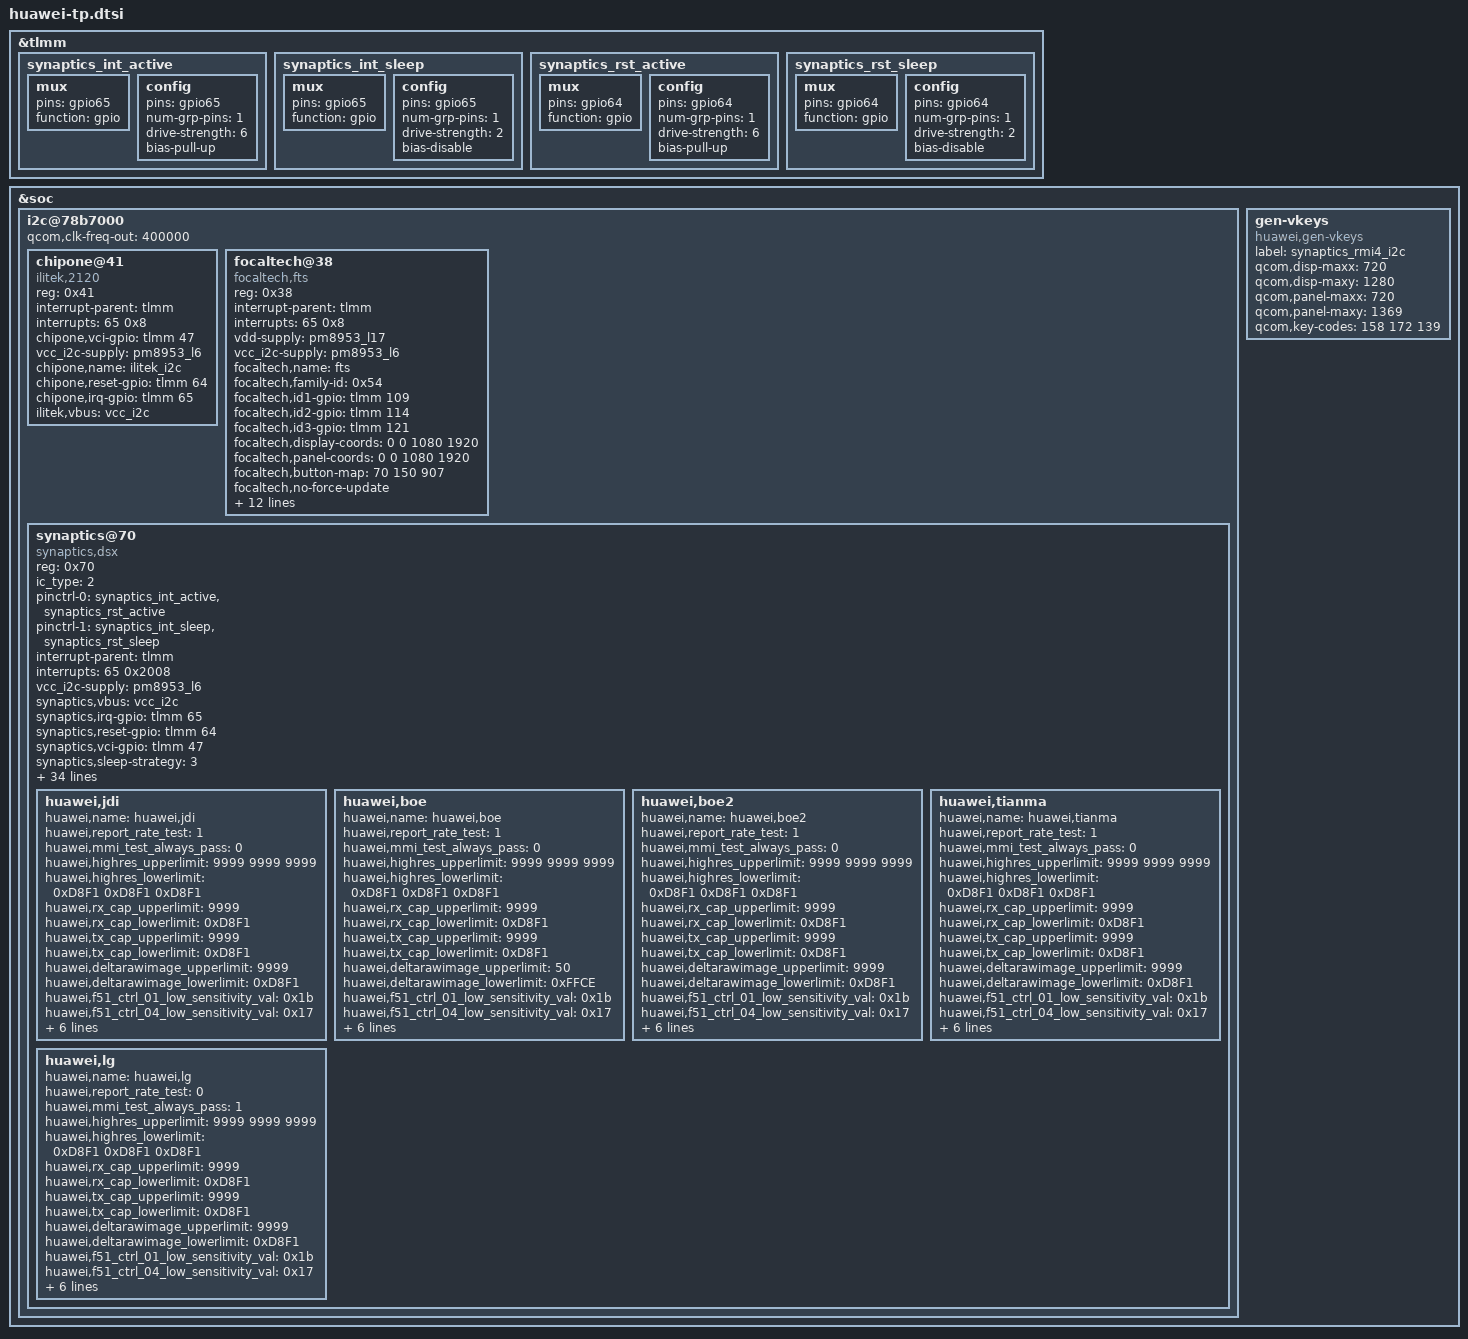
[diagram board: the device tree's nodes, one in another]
/* Modify JDI tp/lcd power on/off to reduce power consumption */
/* Modify JDI tp reset gpio pinctrl for power consumption */
/*Ath TP not working in glove mode*/
/* move l16 control to ATH device config file */
&tlmm {
	synaptics_int_active: synaptics_int_active{
			mux {
				pins = "gpio65";
				function =  "gpio";
			};
			config {
				pins = "gpio65";
				num-grp-pins = <1>;
				drive-strength = <6>;
				bias-pull-up;
		};
	};
	synaptics_int_sleep: synaptics_int_sleep {
			mux {
				pins = "gpio65";
				function =  "gpio";
			};
			config {
				pins = "gpio65";
				num-grp-pins = <1>;
				drive-strength = <2>;
				bias-disable;
		};
	};
	synaptics_rst_active: synaptics_rst_active {
			mux {
				pins = "gpio64";
				function =  "gpio";
			};
			config {
				pins = "gpio64";
				num-grp-pins = <1>;
				drive-strength = <6>;
				bias-pull-up;
			};
		};
	synaptics_rst_sleep: synaptics_rst_sleep {
			mux {
				pins = "gpio64";
				function =  "gpio";
			};
			config {
				pins = "gpio64";
				num-grp-pins = <1>;
				drive-strength = <2>;
				bias-disable;
		};
	};
};

&soc {
	i2c@78b7000 { /* BLSP1 QUP5 */
		status = "ok";
		#address-cells = <1>;
		#size-cells = <0>;
		qcom,clk-freq-out = <400000>;
		chipone@41{
			compatible = "ilitek,2120";
			reg = <0x41>;
			interrupt-parent = <&tlmm>;
			interrupts = <65 0x8>;
			chipone,vci-gpio = <&tlmm 47 0x0>;
			vcc_i2c-supply = <&pm8953_l6>;
			chipone,name = "ilitek_i2c";
			chipone,reset-gpio = <&tlmm 64 0x00>;
			chipone,irq-gpio = <&tlmm 65 0x00>;
			ilitek,vbus = "vcc_i2c";
		};
		focaltech@38 {
		compatible = "focaltech,fts"; 
		reg = <0x38>; 
		interrupt-parent = <&tlmm>; 
		interrupts = <65 0x8>; 
		vdd-supply = <&pm8953_l17>;
		vcc_i2c-supply = <&pm8953_l6>;
		focaltech,name = "fts"; 
		focaltech,family-id = <0x54>; 
		//focaltech,reset-gpio = <&tlmm 64 0x00>; 
		//focaltech,irq-gpio =<&tlmm 65 0x00>; 
		focaltech,id1-gpio = <&tlmm 109 0x00>; 
		focaltech,id2-gpio = <&tlmm 114 0x00>; 
		focaltech,id3-gpio = <&tlmm 121 0x00>; 
		focaltech,display-coords = <0 0 1080 1920>; 
		focaltech,panel-coords = <0 0 1080 1920>; 
		focaltech,button-map= <70 150 907>; 
		focaltech,no-force-update; 
		focaltech,i2c-pull-up; 
		focaltech,group-id = <1>; 
		focaltech,hard-reset-delay-ms = <20>; 
		focaltech,soft-reset-delay-ms = <150>; 
		focaltech,num-max-touches = <10>; 
		focaltech,fw-name = "FT_Upgrade_App.i"; 
		focaltech,fw-delay-aa-ms = <50>; 
		focaltech,fw-delay-55-ms = <30>; 
		focaltech,fw-upgrade-id1 = <0x79>; 
		focaltech,fw-upgrade-id2 = <0x03>; 
		focaltech,fw-delay-readid-ms = <10>; 
		focaltech,fw-delay-era-flsh-ms = <2000>;		
		};
		synaptics@70 {
			compatible = "synaptics,dsx";
			reg = <0x70>;

			/* SYNAPTICS_S3207 = 0 */
			/* SYNAPTICS_S3350 = 1 */
			/* SYNAPTICS_S3320 = 2 */
			/* SYNAPTICS_S3718 = 3 */
			ic_type = <2>;

			pinctrl-names = "active","sleep";
			pinctrl-0 = <&synaptics_int_active &synaptics_rst_active>;
			pinctrl-1 = <&synaptics_int_sleep &synaptics_rst_sleep>;

			interrupt-parent = <&tlmm>;
			interrupts = <65 0x2008>;
			//vdd-supply = <&pm8953_l17>;
			vcc_i2c-supply = <&pm8953_l6>;
			/* Some of qcom's param will not be replaced by huawei in dtb, */
			/* just ignore them:such as "pinctrl-names","pinctrl-0","pinctrl-1", */
			/* "synaptics,display-coords","synaptics,panel-coords","synaptics,i2c-pull-up", */
			/* "synaptics,power-down","synaptics,disable-gpios"*/
			//synaptics,vdd = "vdd";
			synaptics,vbus = "vcc_i2c";
			synaptics,irq-gpio = <&tlmm 65 0x2008>;
			synaptics,reset-gpio = <&tlmm 64 0x0>;
			synaptics,vci-gpio = <&tlmm 47 0x0>;

			/* synaptics,sleep/wake strategy */

			/* SLEEP_STRATEGY_DEEP_SLEEP    : 0*/
			/* SLEEP_STRATEGY_POWER_DOWN    : 1*/
			/* SLEEP_STRATEGY_KEEP_WAKE     : 2*/
			/* SLEEP_STRATEGY_ALWAYS_RESET  : 3*/
			synaptics,sleep-strategy = <3>;

			synaptics,lcd-x = <1080>;
			synaptics,lcd-y = <1920>;
			synaptics,lcd-all = <1920>;
			synaptics,virtual_keys = /* KeyCode CenterX CenterY Width Height */
				/* KEY_BACK */
				<158 142 1342 150 100
				/* KEY_HOME(172) */
				172 360 1342 150 100
				/* KEY_MENU */
				139 578 1342 150 100>;
			synaptics,shutdown_flag = <1>;
			synaptics,appinfo_display_flag = <1>;
			/* SYNAPTICS_WAKE_UP_GESTURE_FLAG:'1'->enabled,'0'->disabled */
			/*IC flash is not enough for holster,so fw del one gesture*/
			synaptics,gesture_enabled = <0>;
			/* Gestures that supported:                           */
			/* bit0  Double tap                                        */
			/* bit1  Single finger slide from left to right     */
			/* bit2  Single finger slide from right to left     */
			/* bit3  Single finger slide from top to bottom  */
			/* bit4  Single finger slide from bottom to top  */
			/* bit5  Double finger slide from top to bottom--disable for holster*/
			/* bit6  Single finger slide circle                     */
			/* bit7  Single finger write letter c                  */
			/* bit8  Single finger write letter e                  */
			/* bit9  Single finger write letter m                 */
			/* bit10 Single finger write letter w                 */
			/* bit11 Palm off screen                                */
			synaptics,easy_wakeup_supported_gestures = <0xF81>;

			/*Defination of report key value  for different gestures*/
			synaptics,easy_wakeup_gesture_keys =
			<	59 /*0.Double tap:                                  KEY_F1*/
				60 /*1.Single finger slide from left to right:      KEY_F2*/
				61 /*2.Single finger slide from right to left:      KEY_F3*/
				62 /*3.Single finger slide from top to bottom:      KEY_F4*/
				63 /*4.Single finger slide from bottom to top:      KEY_F5*/
				64 /*5.Single finger slide circle clockwise:        KEY_F6*/
				65 /*6.Single finger slide circle counter-clockwise:KEY_F7*/
				66 /*7.Single finger write letter c:                KEY_F8*/
				67 /*8.Single finger write letter e:                KEY_F9*/
				68 /*9.Single finger write letter m:                KEY_F10*/
				87 /*10.Single finger write letter w:               KEY_F11*/
				88 /*11.Palm off screen:                            KEY_F12*/
			>;

			/* Double-tap-zone defined by huawei */
			/* Shielded area is:1cm left,1cm right,3cm up,2cm down */
			huawei,dtz_x0 = <1>;
			huawei,dtz_y0 = <1>;
			huawei,dtz_x1 = <1080>;
			huawei,dtz_y1 = <1920>;

			/* GLOVE FLAG default state:'1'->enabled,'0'->disabled*/
			synaptics,glove_enabled = <0>;
			/*After reduce power-consumption by exit reduce mode,*/
			/*we have to reduce f-r rate to make sure gesture work fine*/
			synaptics,fast_relax_gesture = <0>;
			/*Holster support flag*/
			synaptics,holster_supported = <1>;
			synaptics,glove_edge_switch_supported = <0>;
			synaptics,grip_algorithm_supported = <0>;
			synaptics,grip_algorithm_enabled = <0>;
			huawei,grip_left_lsb = <0x32>;
			huawei,grip_left_msb = <0x0>;
			huawei,grip_right_lsb = <0x1A>;
			huawei,grip_right_msb = <0x04>;

			/*dwt represent doze wakeup threshold in gesture mode*/
			synaptics,ofilm_dwt = <30>;
			synaptics,truly_dwt = <30>;
			synaptics,junda_dwt = <30>;

			synaptics,reset-on-status = <0>;
			synaptics,power-delay-ms = <160>;
			synaptics,reset-delay-ms = <200>;
			synaptics,reset-active-ms = <10>;
			synaptics,product_name = "cannes";

			/*capacitance self-adapt*/
			huawei,jdi {
				huawei,name = "huawei,jdi";
				huawei,report_rate_test = <1>; /* 0:disable test, 1:enable test */
				huawei,mmi_test_always_pass = <0>;

				huawei,highres_upperlimit = <9999 9999 9999>;
				huawei,highres_lowerlimit = <0xD8F1 0xD8F1 0xD8F1>;/* 0xD8F1 == -9999 */

				huawei,rx_cap_upperlimit = <9999>;
				huawei,rx_cap_lowerlimit = <0xD8F1>;

				huawei,tx_cap_upperlimit = <9999>;
				huawei,tx_cap_lowerlimit = <0xD8F1>;

				huawei,deltarawimage_upperlimit = <9999>;
				huawei,deltarawimage_lowerlimit = <0xD8F1>;

				huawei,f51_ctrl_01_low_sensitivity_val = <0x1b>;
				huawei,f51_ctrl_04_low_sensitivity_val = <0x17>;
				huawei,f01_ctrl_05_low_sensitivity_val = <0x05>;
				huawei,f01_ctrl_09_low_sensitivity_val = <0x04>;

				huawei,fullraw_upperlimit =
					<9999 9999 9999 9999 9999 9999 9999 9999 9999 9999 9999 9999 9999 9999 9999 9999 9999 9999 9999 9999 9999 9999 9999 9999 9999 9999 9999 9999
					9999 9999 9999 9999 9999 9999 9999 9999 9999 9999 9999 9999 9999 9999 9999 9999 9999 9999 9999 9999 9999 9999 9999 9999 9999 9999 9999 9999
					9999 9999 9999 9999 9999 9999 9999 9999 9999 9999 9999 9999 9999 9999 9999 9999 9999 9999 9999 9999 9999 9999 9999 9999 9999 9999 9999 9999
					9999 9999 9999 9999 9999 9999 9999 9999 9999 9999 9999 9999 9999 9999 9999 9999 9999 9999 9999 9999 9999 9999 9999 9999 9999 9999 9999 9999
					9999 9999 9999 9999 9999 9999 9999 9999 9999 9999 9999 9999 9999 9999 9999 9999 9999 9999 9999 9999 9999 9999 9999 9999 9999 9999 9999 9999
					9999 9999 9999 9999 9999 9999 9999 9999 9999 9999 9999 9999 9999 9999 9999 9999 9999 9999 9999 9999 9999 9999 9999 9999 9999 9999 9999 9999
					9999 9999 9999 9999 9999 9999 9999 9999 9999 9999 9999 9999 9999 9999 9999 9999 9999 9999 9999 9999 9999 9999 9999 9999 9999 9999 9999 9999
					9999 9999 9999 9999 9999 9999 9999 9999 9999 9999 9999 9999 9999 9999 9999 9999 9999 9999 9999 9999 9999 9999 9999 9999 9999 9999 9999 9999
					9999 9999 9999 9999 9999 9999 9999 9999 9999 9999 9999 9999 9999 9999 9999 9999 9999 9999 9999 9999 9999 9999 9999 9999 9999 9999 9999 9999
					9999 9999 9999 9999 9999 9999 9999 9999 9999 9999 9999 9999 9999 9999 9999 9999 9999 9999 9999 9999 9999 9999 9999 9999 9999 9999 9999 9999
					9999 9999 9999 9999 9999 9999 9999 9999 9999 9999 9999 9999 9999 9999 9999 9999 9999 9999 9999 9999 9999 9999 9999 9999 9999 9999 9999 9999
					9999 9999 9999 9999 9999 9999 9999 9999 9999 9999 9999 9999 9999 9999 9999 9999 9999 9999 9999 9999 9999 9999 9999 9999 9999 9999 9999 9999
					9999 9999 9999 9999 9999 9999 9999 9999 9999 9999 9999 9999 9999 9999 9999 9999 9999 9999 9999 9999 9999 9999 9999 9999 9999 9999 9999 9999
					9999 9999 9999 9999 9999 9999 9999 9999 9999 9999 9999 9999 9999 9999 9999 9999 9999 9999 9999 9999 9999 9999 9999 9999 9999 9999 9999 9999
					9999 9999 9999 9999 9999 9999 9999 9999 9999 9999 9999 9999 9999 9999 9999 9999 9999 9999 9999 9999 9999 9999 9999 9999 9999 9999 9999 9999
					9999 9999 9999 9999 9999 9999 9999 9999 9999 9999 9999 9999 9999 9999 9999 9999 9999 9999 9999 9999 9999 9999 9999 9999 9999 9999 9999 9999>;

				huawei,fullraw_lowerlimit =
					<0 0 0 0 0 0 0 0 0 0 0 0 0 0 0 0 0 0 0 0 0 0 0 0 0 0 0 0
					0 0 0 0 0 0 0 0 0 0 0 0 0 0 0 0 0 0 0 0 0 0 0 0 0 0 0 0
					0 0 0 0 0 0 0 0 0 0 0 0 0 0 0 0 0 0 0 0 0 0 0 0 0 0 0 0
					0 0 0 0 0 0 0 0 0 0 0 0 0 0 0 0 0 0 0 0 0 0 0 0 0 0 0 0
					0 0 0 0 0 0 0 0 0 0 0 0 0 0 0 0 0 0 0 0 0 0 0 0 0 0 0 0
					0 0 0 0 0 0 0 0 0 0 0 0 0 0 0 0 0 0 0 0 0 0 0 0 0 0 0 0
					0 0 0 0 0 0 0 0 0 0 0 0 0 0 0 0 0 0 0 0 0 0 0 0 0 0 0 0
					0 0 0 0 0 0 0 0 0 0 0 0 0 0 0 0 0 0 0 0 0 0 0 0 0 0 0 0
					0 0 0 0 0 0 0 0 0 0 0 0 0 0 0 0 0 0 0 0 0 0 0 0 0 0 0 0
					0 0 0 0 0 0 0 0 0 0 0 0 0 0 0 0 0 0 0 0 0 0 0 0 0 0 0 0
					0 0 0 0 0 0 0 0 0 0 0 0 0 0 0 0 0 0 0 0 0 0 0 0 0 0 0 0
					0 0 0 0 0 0 0 0 0 0 0 0 0 0 0 0 0 0 0 0 0 0 0 0 0 0 0 0
					0 0 0 0 0 0 0 0 0 0 0 0 0 0 0 0 0 0 0 0 0 0 0 0 0 0 0 0
					0 0 0 0 0 0 0 0 0 0 0 0 0 0 0 0 0 0 0 0 0 0 0 0 0 0 0 0
					0 0 0 0 0 0 0 0 0 0 0 0 0 0 0 0 0 0 0 0 0 0 0 0 0 0 0 0
					0 0 0 0 0 0 0 0 0 0 0 0 0 0 0 0 0 0 0 0 0 0 0 0 0 0 0 0>;
			};

			huawei,boe {
				huawei,name = "huawei,boe";
				huawei,report_rate_test = <1>; /* 0:disable test, 1:enable test */
				huawei,mmi_test_always_pass = <0>;

				huawei,highres_upperlimit = <9999 9999 9999>;
				huawei,highres_lowerlimit = <0xD8F1 0xD8F1 0xD8F1>;/* 0xD8F1 == -9999 */

				huawei,rx_cap_upperlimit = <9999>;
				huawei,rx_cap_lowerlimit = <0xD8F1>;

				huawei,tx_cap_upperlimit = <9999>;
				huawei,tx_cap_lowerlimit = <0xD8F1>;

				huawei,deltarawimage_upperlimit = <50>;
				huawei,deltarawimage_lowerlimit = <0xFFCE>;

				huawei,f51_ctrl_01_low_sensitivity_val = <0x1b>;
				huawei,f51_ctrl_04_low_sensitivity_val = <0x17>;
				huawei,f01_ctrl_05_low_sensitivity_val = <0x05>;
				huawei,f01_ctrl_09_low_sensitivity_val = <0x04>;

				huawei,fullraw_upperlimit =
					<3447 3363 3309 3248 3208 3193 3177 3184 3190 3195 3194 3244 3314 3373 3487
					3306 3187 3126 3080 3043 3027 3013 3015 3013 3046 3025 3073 3136 3177 3289
					3314 3181 3111 3072 3032 3022 3016 3016 3007 3042 3025 3076 3111 3169 3298
					3316 3190 3117 3060 3020 3016 3020 3027 3016 3042 3030 3064 3111 3169 3306
					3321 3177 3114 3069 3025 3019 3025 3032 3022 3046 3043 3072 3116 3174 3308
					3328 3187 3117 3067 3030 3022 3027 3033 3027 3054 3046 3079 3117 3174 3312
					3330 3194 3121 3067 3030 3026 3032 3042 3027 3052 3050 3086 3138 3208 3312
					3328 3195 3126 3069 3036 3026 3037 3050 3037 3056 3057 3104 3168 3235 3309
					3314 3188 3120 3060 3033 3016 3037 3046 3033 3045 3052 3090 3168 3231 3292
					3322 3184 3123 3072 3033 3030 3037 3049 3033 3056 3064 3110 3178 3244 3302
					3315 3181 3114 3072 3026 3026 3032 3042 3027 3052 3063 3109 3169 3230 3292
					3312 3181 3114 3062 3027 3026 3032 3037 3027 3052 3050 3094 3153 3214 3282
					3306 3177 3106 3049 3020 3015 3022 3030 3019 3039 3045 3080 3141 3198 3274
					3295 3166 3094 3039 3010 3007 3013 3020 3016 3036 3033 3064 3136 3200 3262
					3288 3158 3091 3032 3004 3002 3002 3009 3007 3027 3015 3050 3109 3181 3253
					3274 3147 3079 3019 3000 2992 2989 3006 2996 3016 3009 3030 3073 3144 3244
					3261 3132 3062 3004 2995 2979 2978 2992 2983 3004 2992 3016 3057 3117 3230
					3241 3110 3050 2985 2972 2962 2958 2976 2968 2992 2976 3000 3025 3091 3208
					3228 3091 3033 2976 2953 2946 2943 2961 2953 2976 2961 2988 3009 3072 3193
					3207 3076 3020 2958 2943 2935 2929 2943 2942 2965 2941 2970 2996 3052 3171
					3184 3057 3007 2942 2931 2923 2911 2923 2929 2952 2922 2958 2995 3043 3151
					3158 3045 2990 2936 2928 2912 2901 2905 2914 2936 2904 2942 2989 3042 3132
					3134 3050 2990 2942 2935 2920 2906 2892 2896 2918 2884 2923 2985 3032 3109
					3116 3050 2989 2949 2936 2920 2908 2896 2881 2904 2868 2906 2968 3015 3084
					3116 3049 2979 2946 2938 2925 2908 2904 2888 2886 2875 2914 2973 3025 3060
					3109 3045 2998 2952 2938 2922 2911 2904 2894 2892 2881 2932 2998 3049 3043
					3314 3253 3207 3163 3130 3110 3109 3144 3088 3099 3088 3127 3195 3238 3253>;

				huawei,fullraw_lowerlimit =
					<1915 1738 1881 1856 1840 1839 1832 1840 1829 1814 1829 1826 1875 1910 1870
					1830 1671 1799 1768 1742 1727 1724 1713 1718 1712 1692 1718 1751 1793 1791
					1841 1679 1773 1743 1699 1695 1680 1684 1660 1679 1671 1696 1699 1742 1753
					1847 1687 1769 1760 1763 1756 1756 1747 1697 1744 1731 1756 1788 1830 1820
					1854 1693 1822 1796 1783 1783 1776 1780 1762 1748 1767 1793 1807 1850 1825
					1857 1700 1825 1789 1773 1756 1743 1755 1748 1751 1743 1732 1781 1834 1808
					1860 1702 1826 1784 1768 1751 1737 1751 1744 1747 1741 1730 1778 1830 1807
					1861 1706 1832 1791 1773 1756 1745 1758 1753 1756 1749 1738 1787 1840 1826
					1855 1700 1824 1799 1786 1786 1780 1789 1776 1762 1781 1803 1816 1863 1830
					1861 1711 1830 1807 1792 1784 1783 1774 1781 1763 1760 1788 1816 1868 1832
					1857 1711 1807 1760 1741 1720 1706 1715 1707 1708 1696 1685 1728 1780 1788
					1763 1712 1668 1631 1608 1592 1592 1579 1588 1585 1569 1599 1637 1686 1704
					1584 1569 1532 1492 1480 1468 1460 1479 1480 1491 1489 1492 1545 1608 1631
					1847 1707 1756 1720 1693 1679 1677 1664 1672 1668 1650 1677 1712 1760 1770
					1843 1704 1767 1737 1732 1732 1730 1717 1724 1718 1699 1725 1760 1805 1812
					1836 1700 1753 1732 1692 1687 1672 1684 1660 1664 1648 1675 1680 1722 1762
					1804 1697 1760 1730 1707 1697 1699 1690 1702 1700 1685 1716 1752 1801 1796
					1824 1690 1793 1769 1749 1737 1736 1724 1732 1725 1708 1735 1766 1812 1791
					1814 1687 1737 1707 1690 1682 1685 1685 1685 1685 1674 1668 1702 1751 1760
					1805 1682 1736 1722 1695 1679 1675 1661 1666 1656 1635 1657 1686 1725 1733
					1624 1578 1529 1494 1472 1462 1466 1457 1469 1469 1455 1486 1523 1574 1594
					1787 1674 1758 1732 1713 1704 1700 1696 1686 1684 1682 1679 1699 1748 1748
					1763 1668 1725 1695 1668 1651 1639 1636 1630 1634 1612 1636 1648 1692 1712
					1730 1660 1688 1657 1629 1612 1596 1609 1585 1588 1572 1594 1598 1641 1684
					1700 1635 1556 1553 1543 1536 1532 1552 1556 1553 1559 1590 1601 1656 1629
					1718 1718 1659 1606 1592 1584 1572 1596 1562 1562 1563 1563 1587 1640 1659
					1616 1599 1554 1517 1491 1488 1473 1476 1471 1475 1460 1484 1512 1548 1554>;
			};
			huawei,boe2{
				huawei,name = "huawei,boe2";
				huawei,report_rate_test = <1>; /* 0:disable test, 1:enable test */
				// if is config item is set to 1, the mmi test will always return pass
				huawei,mmi_test_always_pass = <0>;

				huawei,highres_upperlimit = <9999 9999 9999>;
				huawei,highres_lowerlimit = <0xD8F1 0xD8F1 0xD8F1>;/* 0xD8F1 == -9999 */

				huawei,rx_cap_upperlimit = <9999>;
				huawei,rx_cap_lowerlimit = <0xD8F1>;

				huawei,tx_cap_upperlimit = <9999>;
				huawei,tx_cap_lowerlimit = <0xD8F1>;

				huawei,deltarawimage_upperlimit = <9999>;
				huawei,deltarawimage_lowerlimit = <0xD8F1>;

				huawei,f51_ctrl_01_low_sensitivity_val = <0x1b>;
				huawei,f51_ctrl_04_low_sensitivity_val = <0x17>;
				huawei,f01_ctrl_05_low_sensitivity_val = <0x05>;
				huawei,f01_ctrl_09_low_sensitivity_val = <0x04>;

				huawei,fullraw_upperlimit =
					<9999 9999 9999 9999 9999 9999 9999 9999 9999 9999 9999 9999 9999 9999 9999 9999 9999 9999 9999 9999 9999 9999 9999 9999 9999 9999 9999 9999 9999 9999
					9999 9999 9999 9999 9999 9999 9999 9999 9999 9999 9999 9999 9999 9999 9999 9999 9999 9999 9999 9999 9999 9999 9999 9999 9999 9999 9999 9999 9999 9999
					9999 9999 9999 9999 9999 9999 9999 9999 9999 9999 9999 9999 9999 9999 9999 9999 9999 9999 9999 9999 9999 9999 9999 9999 9999 9999 9999 9999 9999 9999
					9999 9999 9999 9999 9999 9999 9999 9999 9999 9999 9999 9999 9999 9999 9999 9999 9999 9999 9999 9999 9999 9999 9999 9999 9999 9999 9999 9999 9999 9999
					9999 9999 9999 9999 9999 9999 9999 9999 9999 9999 9999 9999 9999 9999 9999 9999 9999 9999 9999 9999 9999 9999 9999 9999 9999 9999 9999 9999 9999 9999
					9999 9999 9999 9999 9999 9999 9999 9999 9999 9999 9999 9999 9999 9999 9999 9999 9999 9999 9999 9999 9999 9999 9999 9999 9999 9999 9999 9999 9999 9999
					9999 9999 9999 9999 9999 9999 9999 9999 9999 9999 9999 9999 9999 9999 9999 9999 9999 9999 9999 9999 9999 9999 9999 9999 9999 9999 9999 9999 9999 9999
					9999 9999 9999 9999 9999 9999 9999 9999 9999 9999 9999 9999 9999 9999 9999 9999 9999 9999 9999 9999 9999 9999 9999 9999 9999 9999 9999 9999 9999 9999
					9999 9999 9999 9999 9999 9999 9999 9999 9999 9999 9999 9999 9999 9999 9999 9999 9999 9999 9999 9999 9999 9999 9999 9999 9999 9999 9999 9999 9999 9999
					9999 9999 9999 9999 9999 9999 9999 9999 9999 9999 9999 9999 9999 9999 9999 9999 9999 9999 9999 9999 9999 9999 9999 9999 9999 9999 9999 9999 9999 9999
					9999 9999 9999 9999 9999 9999 9999 9999 9999 9999 9999 9999 9999 9999 9999 9999 9999 9999 9999 9999 9999 9999 9999 9999 9999 9999 9999 9999 9999 9999
					9999 9999 9999 9999 9999 9999 9999 9999 9999 9999 9999 9999 9999 9999 9999 9999 9999 9999 9999 9999 9999 9999 9999 9999 9999 9999 9999 9999 9999 9999
					9999 9999 9999 9999 9999 9999 9999 9999 9999 9999 9999 9999 9999 9999 9999 9999 9999 9999 9999 9999 9999 9999 9999 9999 9999 9999 9999 9999 9999 9999
					9999 9999 9999 9999 9999 9999 9999 9999 9999 9999 9999 9999 9999 9999 9999 9999 9999 9999 9999 9999 9999 9999 9999 9999 9999 9999 9999 9999 9999 9999
					9999 9999 9999 9999 9999 9999 9999 9999 9999 9999 9999 9999 9999 9999 9999 9999 9999 9999 9999 9999 9999 9999 9999 9999 9999 9999 9999 9999 9999 9999
					9999 9999 9999 9999 9999 9999 9999 9999 9999 9999 9999 9999 9999 9999 9999 9999 9999 9999 9999 9999 9999 9999 9999 9999 9999 9999 9999 9999 9999 9999
					9999 9999 9999 9999 9999 9999 9999 9999 9999 9999 9999 9999 9999 9999 9999 9999 9999 9999 9999 9999 9999 9999 9999 9999 9999 9999 9999 9999 9999 9999
					9999 9999 9999 9999 9999 9999 9999 9999 9999 9999 9999 9999 9999 9999 9999 9999 9999 9999 9999 9999 9999 9999 9999 9999 9999 9999 9999 9999 9999 9999>;

				huawei,fullraw_lowerlimit =
					<0 0 0 0 0 0 0 0 0 0 0 0 0 0 0 0 0 0 0 0 0 0 0 0 0 0 0 0 0 0
					0 0 0 0 0 0 0 0 0 0 0 0 0 0 0 0 0 0 0 0 0 0 0 0 0 0 0 0 0 0
					0 0 0 0 0 0 0 0 0 0 0 0 0 0 0 0 0 0 0 0 0 0 0 0 0 0 0 0 0 0
					0 0 0 0 0 0 0 0 0 0 0 0 0 0 0 0 0 0 0 0 0 0 0 0 0 0 0 0 0 0
					0 0 0 0 0 0 0 0 0 0 0 0 0 0 0 0 0 0 0 0 0 0 0 0 0 0 0 0 0 0
					0 0 0 0 0 0 0 0 0 0 0 0 0 0 0 0 0 0 0 0 0 0 0 0 0 0 0 0 0 0
					0 0 0 0 0 0 0 0 0 0 0 0 0 0 0 0 0 0 0 0 0 0 0 0 0 0 0 0 0 0
					0 0 0 0 0 0 0 0 0 0 0 0 0 0 0 0 0 0 0 0 0 0 0 0 0 0 0 0 0 0
					0 0 0 0 0 0 0 0 0 0 0 0 0 0 0 0 0 0 0 0 0 0 0 0 0 0 0 0 0 0
					0 0 0 0 0 0 0 0 0 0 0 0 0 0 0 0 0 0 0 0 0 0 0 0 0 0 0 0 0 0
					0 0 0 0 0 0 0 0 0 0 0 0 0 0 0 0 0 0 0 0 0 0 0 0 0 0 0 0 0 0
					0 0 0 0 0 0 0 0 0 0 0 0 0 0 0 0 0 0 0 0 0 0 0 0 0 0 0 0 0 0
					0 0 0 0 0 0 0 0 0 0 0 0 0 0 0 0 0 0 0 0 0 0 0 0 0 0 0 0 0 0
					0 0 0 0 0 0 0 0 0 0 0 0 0 0 0 0 0 0 0 0 0 0 0 0 0 0 0 0 0 0
					0 0 0 0 0 0 0 0 0 0 0 0 0 0 0 0 0 0 0 0 0 0 0 0 0 0 0 0 0 0
					0 0 0 0 0 0 0 0 0 0 0 0 0 0 0 0 0 0 0 0 0 0 0 0 0 0 0 0 0 0
					0 0 0 0 0 0 0 0 0 0 0 0 0 0 0 0 0 0 0 0 0 0 0 0 0 0 0 0 0 0
					0 0 0 0 0 0 0 0 0 0 0 0 0 0 0 0 0 0 0 0 0 0 0 0 0 0 0 0 0 0>;
			};
			huawei,tianma{
				huawei,name = "huawei,tianma";
				huawei,report_rate_test = <1>; /* 0:disable test, 1:enable test */
				// if is config item is set to 1, the mmi test will always return pass
				huawei,mmi_test_always_pass = <0>;

				huawei,highres_upperlimit = <9999 9999 9999>;
				huawei,highres_lowerlimit = <0xD8F1 0xD8F1 0xD8F1>;/* 0xD8F1 == -9999 */

				huawei,rx_cap_upperlimit = <9999>;
				huawei,rx_cap_lowerlimit = <0xD8F1>;

				huawei,tx_cap_upperlimit = <9999>;
				huawei,tx_cap_lowerlimit = <0xD8F1>;

				huawei,deltarawimage_upperlimit = <9999>;
				huawei,deltarawimage_lowerlimit = <0xD8F1>;

				huawei,f51_ctrl_01_low_sensitivity_val = <0x1b>;
				huawei,f51_ctrl_04_low_sensitivity_val = <0x17>;
				huawei,f01_ctrl_05_low_sensitivity_val = <0x05>;
				huawei,f01_ctrl_09_low_sensitivity_val = <0x04>;

				huawei,fullraw_upperlimit =
<9999 9999 9999 9999 9999 9999 9999 9999 9999 9999 9999 9999 9999 9999 9999 9999 9999 9999 9999 9999 9999 9999 9999 9999 9999 9999 9999 9999 9999 9999
 9999 9999 9999 9999 9999 9999 9999 9999 9999 9999 9999 9999 9999 9999 9999 9999 9999 9999 9999 9999 9999 9999 9999 9999 9999 9999 9999 9999 9999 9999
 9999 9999 9999 9999 9999 9999 9999 9999 9999 9999 9999 9999 9999 9999 9999 9999 9999 9999 9999 9999 9999 9999 9999 9999 9999 9999 9999 9999 9999 9999
 9999 9999 9999 9999 9999 9999 9999 9999 9999 9999 9999 9999 9999 9999 9999 9999 9999 9999 9999 9999 9999 9999 9999 9999 9999 9999 9999 9999 9999 9999
 9999 9999 9999 9999 9999 9999 9999 9999 9999 9999 9999 9999 9999 9999 9999 9999 9999 9999 9999 9999 9999 9999 9999 9999 9999 9999 9999 9999 9999 9999
 9999 9999 9999 9999 9999 9999 9999 9999 9999 9999 9999 9999 9999 9999 9999 9999 9999 9999 9999 9999 9999 9999 9999 9999 9999 9999 9999 9999 9999 9999
 9999 9999 9999 9999 9999 9999 9999 9999 9999 9999 9999 9999 9999 9999 9999 9999 9999 9999 9999 9999 9999 9999 9999 9999 9999 9999 9999 9999 9999 9999
 9999 9999 9999 9999 9999 9999 9999 9999 9999 9999 9999 9999 9999 9999 9999 9999 9999 9999 9999 9999 9999 9999 9999 9999 9999 9999 9999 9999 9999 9999
 9999 9999 9999 9999 9999 9999 9999 9999 9999 9999 9999 9999 9999 9999 9999 9999 9999 9999 9999 9999 9999 9999 9999 9999 9999 9999 9999 9999 9999 9999
 9999 9999 9999 9999 9999 9999 9999 9999 9999 9999 9999 9999 9999 9999 9999 9999 9999 9999 9999 9999 9999 9999 9999 9999 9999 9999 9999 9999 9999 9999
 9999 9999 9999 9999 9999 9999 9999 9999 9999 9999 9999 9999 9999 9999 9999 9999 9999 9999 9999 9999 9999 9999 9999 9999 9999 9999 9999 9999 9999 9999
 9999 9999 9999 9999 9999 9999 9999 9999 9999 9999 9999 9999 9999 9999 9999 9999 9999 9999 9999 9999 9999 9999 9999 9999 9999 9999 9999 9999 9999 9999
 9999 9999 9999 9999 9999 9999 9999 9999 9999 9999 9999 9999 9999 9999 9999 9999 9999 9999 9999 9999 9999 9999 9999 9999 9999 9999 9999 9999 9999 9999
 9999 9999 9999 9999 9999 9999 9999 9999 9999 9999 9999 9999 9999 9999 9999 9999 9999 9999 9999 9999 9999 9999 9999 9999 9999 9999 9999 9999 9999 9999
 9999 9999 9999 9999 9999 9999 9999 9999 9999 9999 9999 9999 9999 9999 9999 9999 9999 9999 9999 9999 9999 9999 9999 9999 9999 9999 9999 9999 9999 9999
 9999 9999 9999 9999 9999 9999 9999 9999 9999 9999 9999 9999 9999 9999 9999 9999 9999 9999 9999 9999 9999 9999 9999 9999 9999 9999 9999 9999 9999 9999
 9999 9999 9999 9999 9999 9999 9999 9999 9999 9999 9999 9999 9999 9999 9999 9999 9999 9999 9999 9999 9999 9999 9999 9999 9999 9999 9999 9999 9999 9999
 9999 9999 9999 9999 9999 9999 9999 9999 9999 9999 9999 9999 9999 9999 9999 9999 9999 9999 9999 9999 9999 9999 9999 9999 9999 9999 9999 9999 9999 9999>;

				huawei,fullraw_lowerlimit =
<0000 0000 0000 0000 0000 0000 0000 0000 0000 0000 0000 0000 0000 0000 0000 0000 0000 0000 0000 0000 0000 0000 0000 0000 0000 0000 0000 0000 0000 0000
 0000 0000 0000 0000 0000 0000 0000 0000 0000 0000 0000 0000 0000 0000 0000 0000 0000 0000 0000 0000 0000 0000 0000 0000 0000 0000 0000 0000 0000 0000
 0000 0000 0000 0000 0000 0000 0000 0000 0000 0000 0000 0000 0000 0000 0000 0000 0000 0000 0000 0000 0000 0000 0000 0000 0000 0000 0000 0000 0000 0000
 0000 0000 0000 0000 0000 0000 0000 0000 0000 0000 0000 0000 0000 0000 0000 0000 0000 0000 0000 0000 0000 0000 0000 0000 0000 0000 0000 0000 0000 0000
 0000 0000 0000 0000 0000 0000 0000 0000 0000 0000 0000 0000 0000 0000 0000 0000 0000 0000 0000 0000 0000 0000 0000 0000 0000 0000 0000 0000 0000 0000
 0000 0000 0000 0000 0000 0000 0000 0000 0000 0000 0000 0000 0000 0000 0000 0000 0000 0000 0000 0000 0000 0000 0000 0000 0000 0000 0000 0000 0000 0000
 0000 0000 0000 0000 0000 0000 0000 0000 0000 0000 0000 0000 0000 0000 0000 0000 0000 0000 0000 0000 0000 0000 0000 0000 0000 0000 0000 0000 0000 0000
 0000 0000 0000 0000 0000 0000 0000 0000 0000 0000 0000 0000 0000 0000 0000 0000 0000 0000 0000 0000 0000 0000 0000 0000 0000 0000 0000 0000 0000 0000
 0000 0000 0000 0000 0000 0000 0000 0000 0000 0000 0000 0000 0000 0000 0000 0000 0000 0000 0000 0000 0000 0000 0000 0000 0000 0000 0000 0000 0000 0000
 0000 0000 0000 0000 0000 0000 0000 0000 0000 0000 0000 0000 0000 0000 0000 0000 0000 0000 0000 0000 0000 0000 0000 0000 0000 0000 0000 0000 0000 0000
 0000 0000 0000 0000 0000 0000 0000 0000 0000 0000 0000 0000 0000 0000 0000 0000 0000 0000 0000 0000 0000 0000 0000 0000 0000 0000 0000 0000 0000 0000
 0000 0000 0000 0000 0000 0000 0000 0000 0000 0000 0000 0000 0000 0000 0000 0000 0000 0000 0000 0000 0000 0000 0000 0000 0000 0000 0000 0000 0000 0000
 0000 0000 0000 0000 0000 0000 0000 0000 0000 0000 0000 0000 0000 0000 0000 0000 0000 0000 0000 0000 0000 0000 0000 0000 0000 0000 0000 0000 0000 0000
 0000 0000 0000 0000 0000 0000 0000 0000 0000 0000 0000 0000 0000 0000 0000 0000 0000 0000 0000 0000 0000 0000 0000 0000 0000 0000 0000 0000 0000 0000
 0000 0000 0000 0000 0000 0000 0000 0000 0000 0000 0000 0000 0000 0000 0000 0000 0000 0000 0000 0000 0000 0000 0000 0000 0000 0000 0000 0000 0000 0000
 0000 0000 0000 0000 0000 0000 0000 0000 0000 0000 0000 0000 0000 0000 0000 0000 0000 0000 0000 0000 0000 0000 0000 0000 0000 0000 0000 0000 0000 0000
 0000 0000 0000 0000 0000 0000 0000 0000 0000 0000 0000 0000 0000 0000 0000 0000 0000 0000 0000 0000 0000 0000 0000 0000 0000 0000 0000 0000 0000 0000
 0000 0000 0000 0000 0000 0000 0000 0000 0000 0000 0000 0000 0000 0000 0000 0000 0000 0000 0000 0000 0000 0000 0000 0000 0000 0000 0000 0000 0000 0000>;
			};
			huawei,lg {
				huawei,name = "huawei,lg";
				huawei,report_rate_test = <0>; /* 0:disable test, 1:enable test */
				// if is config item is set to 1, the mmi test will always return pass
				huawei,mmi_test_always_pass = <1>;

				huawei,highres_upperlimit = <9999 9999 9999>;
				huawei,highres_lowerlimit = <0xD8F1 0xD8F1 0xD8F1>;/* 0xD8F1 == -9999 */

				huawei,rx_cap_upperlimit = <9999>;
				huawei,rx_cap_lowerlimit = <0xD8F1>;

				huawei,tx_cap_upperlimit = <9999>;
				huawei,tx_cap_lowerlimit = <0xD8F1>;

				huawei,deltarawimage_upperlimit = <9999>;
				huawei,deltarawimage_lowerlimit = <0xD8F1>;

				huawei,f51_ctrl_01_low_sensitivity_val = <0x1b>;
				huawei,f51_ctrl_04_low_sensitivity_val = <0x17>;
				huawei,f01_ctrl_05_low_sensitivity_val = <0x05>;
				huawei,f01_ctrl_09_low_sensitivity_val = <0x04>;

				huawei,fullraw_upperlimit =
					<9999 9999 9999 9999 9999 9999 9999 9999 9999 9999 9999 9999 9999 9999 9999 9999 9999 9999 9999 9999 9999 9999 9999 9999 9999 9999 9999 9999
					9999 9999 9999 9999 9999 9999 9999 9999 9999 9999 9999 9999 9999 9999 9999 9999 9999 9999 9999 9999 9999 9999 9999 9999 9999 9999 9999 9999
					9999 9999 9999 9999 9999 9999 9999 9999 9999 9999 9999 9999 9999 9999 9999 9999 9999 9999 9999 9999 9999 9999 9999 9999 9999 9999 9999 9999
					9999 9999 9999 9999 9999 9999 9999 9999 9999 9999 9999 9999 9999 9999 9999 9999 9999 9999 9999 9999 9999 9999 9999 9999 9999 9999 9999 9999
					9999 9999 9999 9999 9999 9999 9999 9999 9999 9999 9999 9999 9999 9999 9999 9999 9999 9999 9999 9999 9999 9999 9999 9999 9999 9999 9999 9999
					9999 9999 9999 9999 9999 9999 9999 9999 9999 9999 9999 9999 9999 9999 9999 9999 9999 9999 9999 9999 9999 9999 9999 9999 9999 9999 9999 9999
					9999 9999 9999 9999 9999 9999 9999 9999 9999 9999 9999 9999 9999 9999 9999 9999 9999 9999 9999 9999 9999 9999 9999 9999 9999 9999 9999 9999
					9999 9999 9999 9999 9999 9999 9999 9999 9999 9999 9999 9999 9999 9999 9999 9999 9999 9999 9999 9999 9999 9999 9999 9999 9999 9999 9999 9999
					9999 9999 9999 9999 9999 9999 9999 9999 9999 9999 9999 9999 9999 9999 9999 9999 9999 9999 9999 9999 9999 9999 9999 9999 9999 9999 9999 9999
					9999 9999 9999 9999 9999 9999 9999 9999 9999 9999 9999 9999 9999 9999 9999 9999 9999 9999 9999 9999 9999 9999 9999 9999 9999 9999 9999 9999
					9999 9999 9999 9999 9999 9999 9999 9999 9999 9999 9999 9999 9999 9999 9999 9999 9999 9999 9999 9999 9999 9999 9999 9999 9999 9999 9999 9999
					9999 9999 9999 9999 9999 9999 9999 9999 9999 9999 9999 9999 9999 9999 9999 9999 9999 9999 9999 9999 9999 9999 9999 9999 9999 9999 9999 9999
					9999 9999 9999 9999 9999 9999 9999 9999 9999 9999 9999 9999 9999 9999 9999 9999 9999 9999 9999 9999 9999 9999 9999 9999 9999 9999 9999 9999
					9999 9999 9999 9999 9999 9999 9999 9999 9999 9999 9999 9999 9999 9999 9999 9999 9999 9999 9999 9999 9999 9999 9999 9999 9999 9999 9999 9999
					9999 9999 9999 9999 9999 9999 9999 9999 9999 9999 9999 9999 9999 9999 9999 9999 9999 9999 9999 9999 9999 9999 9999 9999 9999 9999 9999 9999
					9999 9999 9999 9999 9999 9999 9999 9999 9999 9999 9999 9999 9999 9999 9999 9999 9999 9999 9999 9999 9999 9999 9999 9999 9999 9999 9999 9999>;

				huawei,fullraw_lowerlimit =
					<0 0 0 0 0 0 0 0 0 0 0 0 0 0 0 0 0 0 0 0 0 0 0 0 0 0 0 0
					0 0 0 0 0 0 0 0 0 0 0 0 0 0 0 0 0 0 0 0 0 0 0 0 0 0 0 0
					0 0 0 0 0 0 0 0 0 0 0 0 0 0 0 0 0 0 0 0 0 0 0 0 0 0 0 0
					0 0 0 0 0 0 0 0 0 0 0 0 0 0 0 0 0 0 0 0 0 0 0 0 0 0 0 0
					0 0 0 0 0 0 0 0 0 0 0 0 0 0 0 0 0 0 0 0 0 0 0 0 0 0 0 0
					0 0 0 0 0 0 0 0 0 0 0 0 0 0 0 0 0 0 0 0 0 0 0 0 0 0 0 0
					0 0 0 0 0 0 0 0 0 0 0 0 0 0 0 0 0 0 0 0 0 0 0 0 0 0 0 0
					0 0 0 0 0 0 0 0 0 0 0 0 0 0 0 0 0 0 0 0 0 0 0 0 0 0 0 0
					0 0 0 0 0 0 0 0 0 0 0 0 0 0 0 0 0 0 0 0 0 0 0 0 0 0 0 0
					0 0 0 0 0 0 0 0 0 0 0 0 0 0 0 0 0 0 0 0 0 0 0 0 0 0 0 0
					0 0 0 0 0 0 0 0 0 0 0 0 0 0 0 0 0 0 0 0 0 0 0 0 0 0 0 0
					0 0 0 0 0 0 0 0 0 0 0 0 0 0 0 0 0 0 0 0 0 0 0 0 0 0 0 0
					0 0 0 0 0 0 0 0 0 0 0 0 0 0 0 0 0 0 0 0 0 0 0 0 0 0 0 0
					0 0 0 0 0 0 0 0 0 0 0 0 0 0 0 0 0 0 0 0 0 0 0 0 0 0 0 0
					0 0 0 0 0 0 0 0 0 0 0 0 0 0 0 0 0 0 0 0 0 0 0 0 0 0 0 0
					0 0 0 0 0 0 0 0 0 0 0 0 0 0 0 0 0 0 0 0 0 0 0 0 0 0 0 0>;
			};
		};
	};

	/*To disable gen-vkeys.c probe,avoid generate kobject*/
	gen-vkeys {
		compatible = "huawei,gen-vkeys";
		label = "synaptics_rmi4_i2c";
		qcom,disp-maxx = <720>;
		qcom,disp-maxy = <1280>;
		qcom,panel-maxx = <720>;
		qcom,panel-maxy = <1369>;
		qcom,key-codes = <158 172 139>;
	};

};
